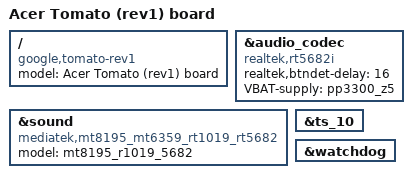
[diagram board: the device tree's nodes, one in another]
// SPDX-License-Identifier: (GPL-2.0 OR MIT)
/*
 * Copyright (C) 2021 MediaTek Inc.
 */
/dts-v1/;
#include "mt8195-cherry.dtsi"

/ {
	model = "Acer Tomato (rev1) board";
	compatible = "google,tomato-rev1", "google,tomato", "mediatek,mt8195";
};

&audio_codec {
	compatible = "realtek,rt5682i";
	realtek,btndet-delay = <16>;
	VBAT-supply = <&pp3300_z5>;
};

&sound {
	compatible = "mediatek,mt8195_mt6359_rt1019_rt5682";
	model = "mt8195_r1019_5682";
};

&ts_10 {
	status = "okay";
};

&watchdog {
	/delete-property/ mediatek,disable-extrst;
};
